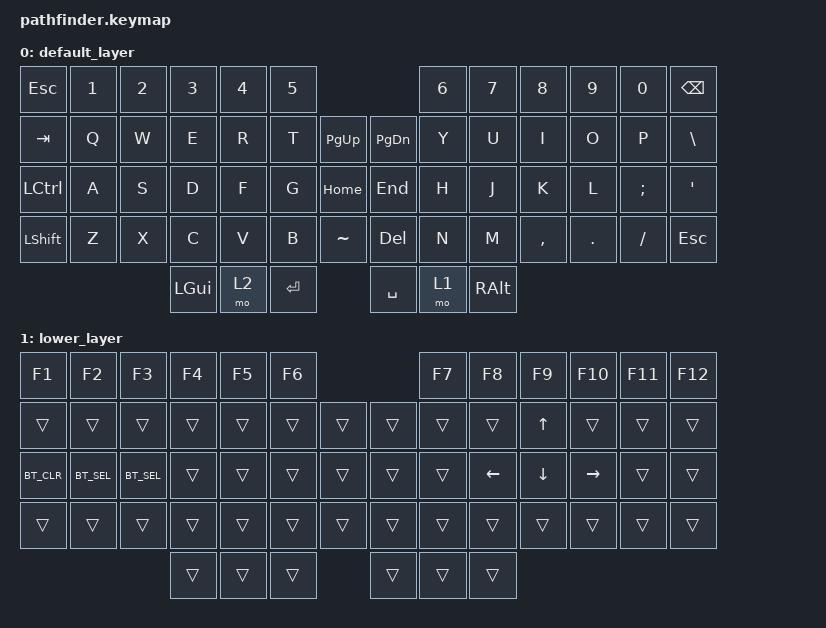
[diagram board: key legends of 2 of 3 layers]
/*
 * Copyright (c) 2020 The ZMK Contributors
 *
 * SPDX-License-Identifier: MIT
 */

#include <behaviors.dtsi>
#include <dt-bindings/zmk/keys.h>
#include <dt-bindings/zmk/bt.h>

/ {
        keymap {
                compatible = "zmk,keymap";

                default_layer {
// -----------------------------------------------------------------------------------------
// |  ESC |  1  |  2  |  3  |  4  |  5  |                        |  6  |  7   |  8  |  9  |  0  | BKSP |
// |  TAB |  Q  |  W  |  E  |  R  |  T  | PG_UP |        | PG_DN |  Y  |  U   |  I  |  O  |  P  |  |   |
// | CTRL |  A  |  S  |  D  |  F  |  G  | HOME  |        |  END  |  H  |  J   |  K  |  L  |  ;  |  '   |
// | SHFT |  Z  |  X  |  C  |  V  |  B  | TILDE |        |  DEL  |  N  |  M   |  ,  |  .  |  /  | ESC  |
//                        | GUI | RSE | RET |               | SPC | LWR  | ALT |
                        bindings = <
   &kp ESC   &kp N1 &kp N2 &kp N3 &kp N4 &kp N5                        &kp N6 &kp N7  &kp N8    &kp N9  &kp N0   &kp BSPC
   &kp TAB   &kp Q  &kp W  &kp E  &kp R  &kp T  &kp PG_UP    &kp PG_DN &kp Y  &kp U   &kp I     &kp O   &kp P    &kp BSLH
   &kp LCTRL &kp A  &kp S  &kp D  &kp F  &kp G  &kp HOME     &kp END   &kp H  &kp J   &kp K     &kp L   &kp SEMI &kp SQT
   &kp LSHFT &kp Z  &kp X  &kp C  &kp V  &kp B  &kp TILDE    &kp DEL   &kp N  &kp M   &kp COMMA &kp DOT &kp FSLH &kp ESC
                              &kp LGUI &mo 2  &kp RET           &kp SPACE &mo 1 &kp RALT
                        >;
                };
                lower_layer {
// -----------------------------------------------------------------------------------------
// |  F1  | F2  | F3  | F4  | F5  | F6  |                      | F7  | F8  | F9  | F10 | F11 |  F12 |
// |      |     |     |     |     |     |     |          |     |     |   |  UP   |     |     |      |
// | BTCLR| BT1 | BT2 | BT3 | BT4 | BT5 |     |          |     |     | LFT | DWN | RGT |     |      |
// |      |     |     |     |     |     |     |          |     |     |     |     |     |     |      |
//                        |     |     |     |              |     |     |     |
                        bindings = <
   &kp F1     &kp F2       &kp F3       &kp F4 &kp F5 &kp F6                    &kp F7   &kp F8   &kp F9   &kp F10   &kp F11 &kp F12
   &trans     &trans       &trans       &trans &trans &trans &trans      &trans &trans   &trans   &kp UP   &trans    &trans  &trans
   &kp BT_CLR &kp BT_SEL 1 &kp BT_SEL 2 &trans &trans &trans &trans      &trans &trans   &kp LEFT &kp DOWN &kp RIGHT &trans  &trans
   &trans     &trans       &trans       &trans &trans &trans &trans      &trans &trans   &trans   &trans   &trans    &trans  &trans
                                        &trans &trans  &trans             &trans &trans &trans
                        >;
                };

                raise_layer {
// -----------------------------------------------------------------------------------------
// |      |     |     |     |     |     |                      |     |     | KP D| KP X| KP -|      |
// |      |     |     |     |     |     |     |          |     |     | KP 7| KP 8| KP 9| KP+ |      |
// |      | PRV |PL/PS|NEXT |VOLU |VOLD |     |          |     |     | KP 4| KP 5| KP 6| KPEN|      |
// |      |     |     |     |     |     |     |          |     |     | KP 1| KP 2| KP 3| KPEN|      |
//                        |     |     |     |              |     |     |     |
                        bindings = <
   &trans &trans     &trans   &trans     &trans &trans                             &trans &trans    &kp KP_SLASH &kp KP_MULTIPLY &kp KP_MINUS &trans
   &trans &trans     &trans   &trans     &trans &trans &trans               &trans &trans &kp KP_N7 &kp KP_N8    &kp KP_N9       &kp KP_PLUS  &trans
   &trans &kp C_PREV &kp C_PP &kp C_NEXT &kp C_VOL_DN &kp C_VOL_UP &trans   &trans &trans &kp KP_N4 &kp KP_N5    &kp KP_N6       &kp KP_ENTER &trans
   &trans &trans     &trans   &trans     &trans &trans &trans               &trans &trans &kp KP_N1 &kp KP_N2    &kp KP_N3 &     &kp KP_ENTER &trans
                                         &trans &trans  &trans              &trans &trans &trans
                        >;
                };
        };
};
